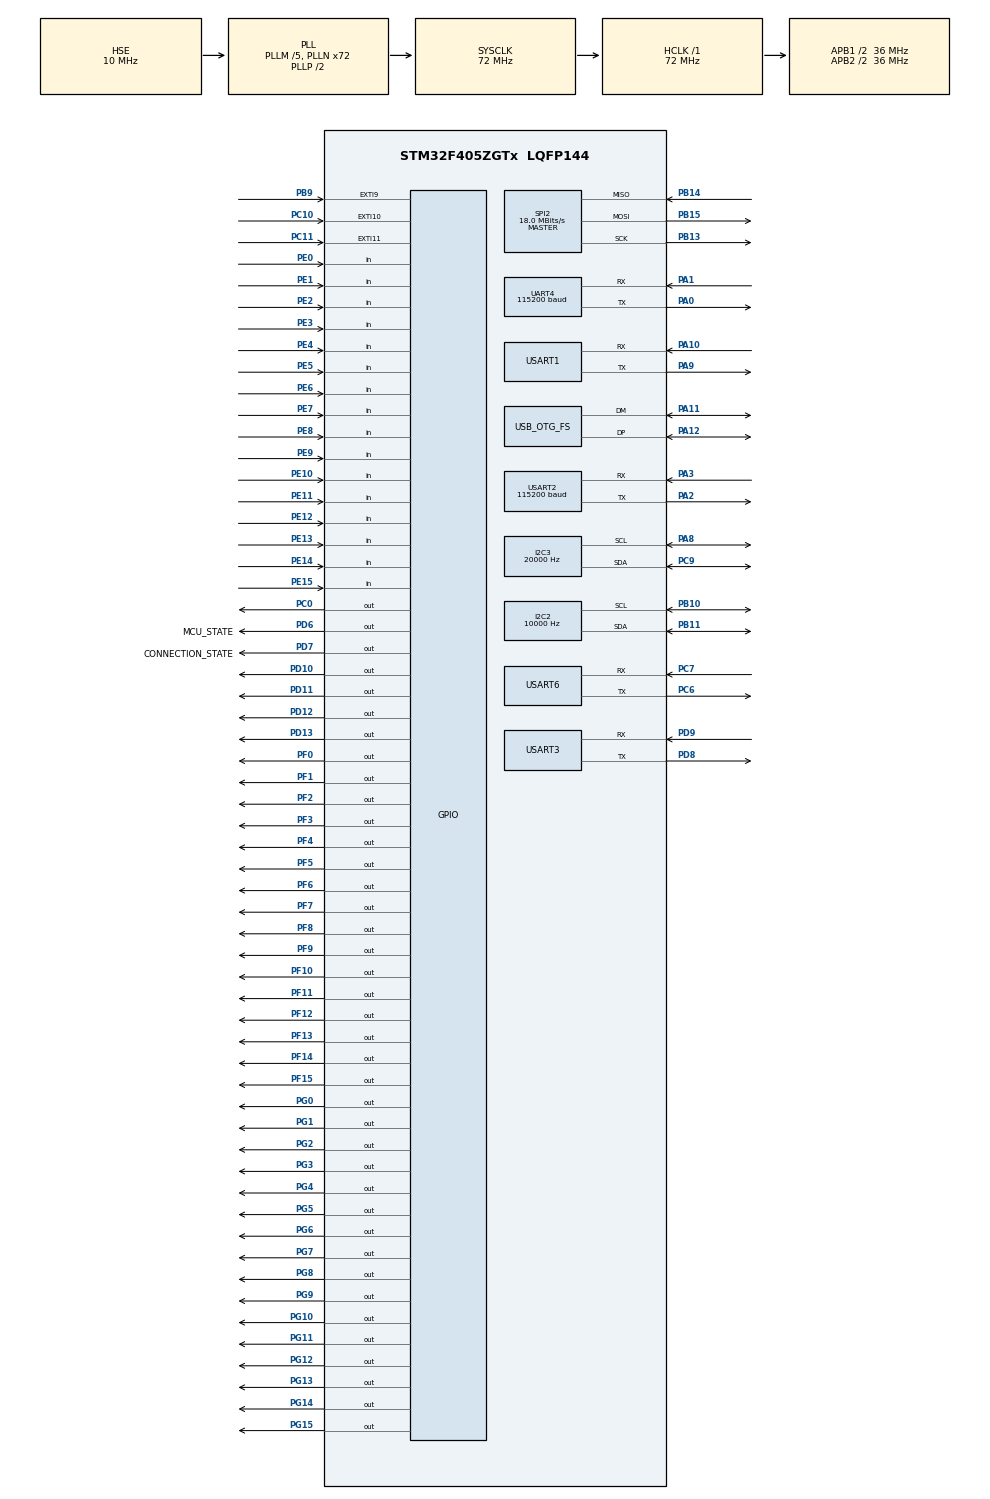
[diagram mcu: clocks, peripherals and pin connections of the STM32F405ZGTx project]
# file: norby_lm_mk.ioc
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Dma.Request0=SPI2_RX
Dma.Request1=SPI2_TX
Dma.SPI2_RX.0.Direction=DMA_PERIPH_TO_MEMORY
Dma.SPI2_RX.0.FIFOMode=DMA_FIFOMODE_DISABLE
Dma.SPI2_RX.0.Instance=DMA1_Stream3
Dma.SPI2_RX.0.MemDataAlignment=DMA_MDATAALIGN_BYTE
Dma.SPI2_RX.0.MemInc=DMA_MINC_ENABLE
Dma.SPI2_RX.0.Mode=DMA_NORMAL
Dma.SPI2_RX.0.PeriphDataAlignment=DMA_PDATAALIGN_BYTE
Dma.SPI2_RX.0.PeriphInc=DMA_PINC_DISABLE
Dma.SPI2_RX.0.Priority=DMA_PRIORITY_LOW
Dma.SPI2_TX.1.Direction=DMA_MEMORY_TO_PERIPH
Dma.SPI2_TX.1.FIFOMode=DMA_FIFOMODE_DISABLE
Dma.SPI2_TX.1.Instance=DMA1_Stream4
Dma.SPI2_TX.1.MemDataAlignment=DMA_MDATAALIGN_BYTE
Dma.SPI2_TX.1.MemInc=DMA_MINC_ENABLE
Dma.SPI2_TX.1.Mode=DMA_NORMAL
Dma.SPI2_TX.1.PeriphDataAlignment=DMA_PDATAALIGN_BYTE
Dma.SPI2_TX.1.PeriphInc=DMA_PINC_DISABLE
Dma.SPI2_TX.1.Priority=DMA_PRIORITY_LOW
I2C2.ClockSpeed=10000
I2C3.ClockSpeed=20000
IWDG.Prescaler=IWDG_PRESCALER_256
IWDG.Reload=4000
Mcu.Family=STM32F4
Mcu.Name=STM32F405ZGTx
Mcu.Package=LQFP144
NVIC.DMA1_Stream3_IRQn=true\:0\:0\:false\:false\:true\:false\:true
NVIC.DMA1_Stream4_IRQn=true\:0\:0\:false\:false\:true\:false\:true
NVIC.EXTI9_5_IRQn=true\:0\:0\:false\:false\:true\:true\:true
NVIC.I2C2_ER_IRQn=true\:0\:0\:false\:false\:true\:true\:true
NVIC.I2C2_EV_IRQn=true\:0\:0\:false\:false\:true\:true\:true
NVIC.I2C3_ER_IRQn=true\:0\:0\:false\:false\:true\:true\:true
NVIC.I2C3_EV_IRQn=true\:0\:0\:false\:false\:true\:true\:true
NVIC.OTG_FS_IRQn=true\:0\:0\:false\:false\:true\:false\:true
NVIC.PriorityGroup=NVIC_PRIORITYGROUP_4
NVIC.SPI2_IRQn=true\:0\:0\:false\:false\:true\:true\:true
NVIC.TIM2_IRQn=true\:0\:0\:false\:false\:true\:true\:true
NVIC.TIM3_IRQn=true\:0\:0\:false\:false\:true\:true\:true
NVIC.TIM5_IRQn=true\:0\:0\:false\:false\:true\:true\:true
NVIC.TIM6_DAC_IRQn=true\:0\:0\:false\:false\:true\:true\:true
NVIC.UART4_IRQn=true\:0\:0\:false\:false\:true\:true\:true
NVIC.USART1_IRQn=true\:0\:0\:false\:false\:true\:true\:true
NVIC.USART2_IRQn=true\:0\:0\:false\:false\:true\:true\:true
NVIC.USART3_IRQn=true\:0\:0\:false\:false\:true\:true\:true
NVIC.USART6_IRQn=true\:0\:0\:false\:false\:true\:true\:true
PA0-WKUP.Mode=Asynchronous
PA0-WKUP.Signal=UART4_TX
PA1.Mode=Asynchronous
PA1.Signal=UART4_RX
PA10.Mode=Asynchronous
PA10.Signal=USART1_RX
PA11.Mode=Device_Only
PA11.Signal=USB_OTG_FS_DM
PA12.Mode=Device_Only
PA12.Signal=USB_OTG_FS_DP
PA13.Mode=Trace_Asynchronous_SW
PA13.Signal=SYS_JTMS-SWDIO
PA14.Mode=Trace_Asynchronous_SW
PA14.Signal=SYS_JTCK-SWCLK
PA2.Mode=Asynchronous
PA2.Signal=USART2_TX
PA3.Mode=Asynchronous
PA3.Signal=USART2_RX
PA8.GPIO_Pu=GPIO_PULLUP
PA8.Mode=I2C
PA8.Signal=I2C3_SCL
PA9.Mode=Asynchronous
PA9.Signal=USART1_TX
PB10.GPIO_Pu=GPIO_PULLUP
PB10.Mode=I2C
PB10.Signal=I2C2_SCL
PB11.GPIO_Pu=GPIO_PULLUP
PB11.Mode=I2C
PB11.Signal=I2C2_SDA
PB13.Mode=Full_Duplex_Master
PB13.Signal=SPI2_SCK
PB14.Mode=Full_Duplex_Master
PB14.Signal=SPI2_MISO
PB15.Mode=Full_Duplex_Master
PB15.Signal=SPI2_MOSI
PB3.Mode=Trace_Asynchronous_SW
PB3.Signal=SYS_JTDO-SWO
PB5.Signal=CAN2_RX
PB6.Signal=CAN2_TX
PB9.GPIO_ModeDefaultEXTI=GPIO_MODE_IT_RISING_FALLING
PB9.GPIO_PuPd=GPIO_PULLUP
PB9.Signal=GPXTI9
PC0.Signal=GPIO_Output
PC10.GPIO_ModeDefaultEXTI=GPIO_MODE_IT_RISING_FALLING
PC10.GPIO_PuPd=GPIO_PULLUP
PC10.Signal=GPXTI10
PC11.GPIO_ModeDefaultEXTI=GPIO_MODE_IT_RISING_FALLING
PC11.GPIO_PuPd=GPIO_PULLUP
PC11.Signal=GPXTI11
PC6.Mode=Asynchronous
PC6.Signal=USART6_TX
PC7.Mode=Asynchronous
PC7.Signal=USART6_RX
PC9.GPIO_Pu=GPIO_PULLUP
PC9.Mode=I2C
PC9.Signal=I2C3_SDA
PD0.Signal=CAN1_RX
PD1.Signal=CAN1_TX
PD10.GPIO_Speed=GPIO_SPEED_FREQ_VERY_HIGH
PD10.PinState=GPIO_PIN_SET
PD10.Signal=GPIO_Output
PD11.GPIO_Speed=GPIO_SPEED_FREQ_VERY_HIGH
PD11.PinState=GPIO_PIN_SET
PD11.Signal=GPIO_Output
PD12.GPIO_Speed=GPIO_SPEED_FREQ_VERY_HIGH
PD12.PinState=GPIO_PIN_SET
PD12.Signal=GPIO_Output
PD13.GPIO_Speed=GPIO_SPEED_FREQ_VERY_HIGH
PD13.PinState=GPIO_PIN_SET
PD13.Signal=GPIO_Output
PD6.GPIO_Label=MCU_STATE
PD6.Signal=GPIO_Output
PD7.GPIO_Label=CONNECTION_STATE
PD7.Signal=GPIO_Output
PD8.Mode=Asynchronous
PD8.Signal=USART3_TX
PD9.Mode=Asynchronous
PD9.Signal=USART3_RX
PE0.Signal=GPIO_Input
PE1.Signal=GPIO_Input
PE10.Signal=GPIO_Input
PE11.Signal=GPIO_Input
PE12.Signal=GPIO_Input
PE13.Signal=GPIO_Input
PE14.Signal=GPIO_Input
PE15.Signal=GPIO_Input
PE2.Signal=GPIO_Input
PE3.Signal=GPIO_Input
PE4.Signal=GPIO_Input
PE5.Signal=GPIO_Input
PE6.Signal=GPIO_Input
PE7.Signal=GPIO_Input
PE8.Signal=GPIO_Input
PE9.Signal=GPIO_Input
PF0.Signal=GPIO_Output
PF1.Signal=GPIO_Output
PF10.Signal=GPIO_Output
PF11.Signal=GPIO_Output
PF12.Signal=GPIO_Output
PF13.Signal=GPIO_Output
PF14.Signal=GPIO_Output
PF15.Signal=GPIO_Output
PF2.Signal=GPIO_Output
PF3.Signal=GPIO_Output
PF4.Signal=GPIO_Output
PF5.Signal=GPIO_Output
PF6.Signal=GPIO_Output
PF7.Signal=GPIO_Output
PF8.Signal=GPIO_Output
PF9.Signal=GPIO_Output
PG0.Signal=GPIO_Output
PG1.Signal=GPIO_Output
PG10.Signal=GPIO_Output
PG11.Signal=GPIO_Output
PG12.Signal=GPIO_Output
PG13.Signal=GPIO_Output
PG14.Signal=GPIO_Output
PG15.Signal=GPIO_Output
PG2.Signal=GPIO_Output
PG3.Signal=GPIO_Output
PG4.Signal=GPIO_Output
PG5.Signal=GPIO_Output
PG6.Signal=GPIO_Output
PG7.Signal=GPIO_Output
PG8.Signal=GPIO_Output
PG9.Signal=GPIO_Output
PH0-OSC_IN.Mode=HSE-External-Oscillator
PH0-OSC_IN.Signal=RCC_OSC_IN
PH1-OSC_OUT.Mode=HSE-External-Oscillator
PH1-OSC_OUT.Signal=RCC_OSC_OUT
ProjectManager.HeapSize=0x400
ProjectManager.StackSize=0x800
ProjectManager.TargetToolchain=MDK-ARM V5.32
RCC.48MHZClocksFreq_Value=48000000
RCC.AHBFreq_Value=72000000
RCC.APB1CLKDivider=RCC_HCLK_DIV2
RCC.APB1Freq_Value=36000000
RCC.APB1TimFreq_Value=72000000
RCC.APB2CLKDivider=RCC_HCLK_DIV2
RCC.APB2Freq_Value=36000000
RCC.APB2TimFreq_Value=72000000
RCC.CortexFreq_Value=72000000
RCC.HCLKFreq_Value=72000000
RCC.HSE_VALUE=10000000
RCC.HSI_VALUE=16000000
RCC.LSE_VALUE=32768
RCC.PLLM=5
RCC.PLLN=72
RCC.PLLQ=3
RCC.RCC_RTC_Clock_SourceVirtual=RCC_RTCCLKSOURCE_HSE_DIV10
RCC.RCC_RTC_Clock_Source_FROM_HSE=RCC_RTCCLKSOURCE_HSE_DIV10
RCC.SYSCLKFreq_VALUE=72000000
RCC.SYSCLKSource=RCC_SYSCLKSOURCE_PLLCLK
RCC.VCOOutputFreq_Value=144000000
RTC.AsynchPrediv=124
RTC.Format=RTC_FORMAT_BIN
RTC.SynchPrediv=7999
SPI2.BaudRatePrescaler=SPI_BAUDRATEPRESCALER_2
SPI2.CalculateBaudRate=18.0 MBits/s
SPI2.Direction=SPI_DIRECTION_2LINES
SPI2.Mode=SPI_MODE_MASTER
SPI2.VirtualType=VM_MASTER
TIM2.Period=1000000
TIM2.Prescaler=71
TIM3.AutoReloadPreload=TIM_AUTORELOAD_PRELOAD_ENABLE
TIM3.Period=1000
TIM3.Prescaler=7199
TIM5.CounterMode=TIM_COUNTERMODE_DOWN
TIM5.Period=1000
TIM5.Prescaler=71
TIM6.AutoReloadPreload=TIM_AUTORELOAD_PRELOAD_ENABLE
TIM6.Period=50
TIM6.Prescaler=7199
UART4.BaudRate=115200
UART4.VirtualMode=Asynchronous
USART1.VirtualMode=VM_ASYNC
USART2.BaudRate=115200
USART2.StopBits=STOPBITS_2
USART2.VirtualMode=VM_ASYNC
USART3.VirtualMode=VM_ASYNC
USART6.VirtualMode=VM_ASYNC
USB_DEVICE.CLASS_NAME_FS=CDC
USB_DEVICE.MANUFACTURER_STRING-CDC_FS=Norby_Linking_Module
USB_DEVICE.PRODUCT_STRING_CDC_FS=Norby_LM Virtual ComPort
USB_DEVICE.VirtualMode-CDC_FS=Cdc
USB_DEVICE.VirtualModeFS=Cdc_FS
USB_OTG_FS.VirtualMode=Device_Only
VP_IWDG_VS_IWDG.Mode=IWDG_Activate
VP_RTC_VS_RTC_Activate.Mode=RTC_Enabled
VP_RTC_VS_RTC_Calendar.Mode=RTC_Calendar
VP_TIM2_VS_ClockSourceINT.Mode=Internal
VP_TIM3_VS_ClockSourceINT.Mode=Internal
VP_TIM5_VS_ClockSourceINT.Mode=Internal
VP_TIM5_VS_OPM.Mode=OPM_bit
VP_TIM6_VS_ClockSourceINT.Mode=Enable_Timer
VP_USB_DEVICE_VS_USB_DEVICE_CDC_FS.Mode=CDC_FS
board=custom

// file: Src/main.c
/* USER CODE BEGIN Header */
/**
  ******************************************************************************
  * @file           : main.c
  * @brief          : Main program body
  ******************************************************************************
  * @attention
  *
  * <h2><center>&copy; Copyright (c) 2020 STMicroelectronics.
  * All rights reserved.</center></h2>
  *
  * This software component is licensed by ST under Ultimate Liberty license
  * SLA0044, the "License"; You may not use this file except in compliance with
  * the License. You may obtain a copy of the License at:
  *                             www.st.com/SLA0044
  *
  ******************************************************************************
  */
/* USER CODE END Header */
#include "main.h"
#include "dma.h"
#include "i2c.h"
#include "iwdg.h"
#include "rtc.h"
#include "spi.h"
#include "tim.h"
#include "usart.h"
#include "usb_device.h"
#include "gpio.h"

/* USER CODE BEGIN Includes */
#include <stdio.h>

//#include "lm.h"
//#include "lm_int_cb.h"
//#include "can_vcp.h"
#include "vcp_time_segmentation.h"
#include "led.h"
#include "cy15b104qn_spi.h"
//test//
#include "modbus.h"
#include "pwr_ch.h"
//test_end//
/* USER CODE END Includes */

/* USER CODE BEGIN PV */
type_VCP_UART vcp;
//type_CAN_VCP can_vcp;
//type_LM_DEVICE lm;
type_MODBUS mb;
type_PWR_CHANNEL sol_pwr_ch;
type_LED_INDICATOR mcu_state_led, con_state_led;

uint8_t tx_data[256], tx_data_len=0; //масив для формирования данных для отправки через VCP
uint8_t rx_data[256], rx_data_len=0;
uint8_t time_slot_flag_100ms = 0, time_slot_flag_10ms = 0, time_slot_flag_5ms = 0, time_slot_flag_1s = 0;
uint8_t timer_slot_5ms_counter = 0;
uint8_t uint8_val = 0, uint8_buff[128] = {0};
uint16_t uint16_val = 0;
int16_t int16_val = 0;
int8_t int8_val = 0;
char str[128];
/* USER CODE END PV */

void SystemClock_Config(void);
/* USER CODE BEGIN PFP */
void blocking_test(void);
/* USER CODE END PFP */

int main(void)
{

  /* MCU Configuration--------------------------------------------------------*/

  /* Reset of all peripherals, Initializes the Flash interface and the Systick. */
  HAL_Init();

  /* Configure the system clock */
  SystemClock_Config();

  /* Initialize all configured peripherals */
  MX_GPIO_Init();
  MX_USB_DEVICE_Init();
  MX_TIM5_Init();
  MX_I2C3_Init();
  MX_TIM6_Init();
  MX_TIM2_Init();
  MX_TIM3_Init();
  MX_I2C2_Init();
  MX_RTC_Init();
  MX_UART4_Init();
  MX_USART2_UART_Init();
  MX_SPI2_Init();
  MX_USART1_UART_Init();
  MX_USART3_UART_Init();
  MX_USART6_UART_Init();
  MX_DMA_Init();
  MX_IWDG_Init();
  /* USER CODE BEGIN 2 */
  //lm_init(&lm);
  //ProcCallbackCmds_Init();
  //can_vcp_init(&can_vcp, &vcp);
  //
  //lm_load_parameters(&lm);
  //led init
  led_init(&mcu_state_led, GPIOD, 6);
  led_init(&con_state_led, GPIOD, 7);
  led_setup(&con_state_led, LED_OFF, 0, 0);
  led_setup(&mcu_state_led, LED_HEART_BEAT, 1000, 0);
  led_alt_setup(&con_state_led, LED_BLINK, 200, 127, 2000);
  led_alt_setup(&mcu_state_led, LED_BLINK, 200, 127, 2000);
  //
  HAL_TIM_Base_Start_IT(&htim6); //LED and 10ms_slot timer
  HAL_TIM_Base_Start_IT(&htim2); //global clock timer
  HAL_TIM_Base_Start_IT(&htim3); //100ms time slot timer
  //
  HAL_UART_Receive_IT(&huart2, mb.rx_data, 1);
  //HAL_UART_Receive_IT(lm.pl._11B.interface.tr_lvl.huart, lm.pl._11B.interface.tr_lvl.rx_data, 1);
  //HAL_UART_Receive_IT(lm.pl._12.interface.tr_lvl.huart, lm.pl._12.interface.tr_lvl.rx_data, 1);
  //HAL_UART_Receive_IT(lm.pl._20.interface.huart, lm.pl._20.interface.rx_data, 1);

  //
  __HAL_DBGMCU_FREEZE_IWDG();
	//
	blocking_test();
  /* USER CODE END 2 */

  /* Infinite loop */
  /* USER CODE BEGIN WHILE */

  while (1)
  {
    if (time_slot_flag_1s){ // 1s
      // сохраняем рабочие параметры
      //lm_save_parameters(&lm);
      //reset flag
			time_slot_flag_1s = 0;
    }
		if (time_slot_flag_100ms){ // 100ms
      // сохраняем время в управляющую струткуру
      //lm.ctrl.global_time_s = clock_get_time_s();
			//формирование кадров телеметрии
      //fill_tmi_and_beacon(&lm);
      //fill_gen_tmi(&lm);
			//опрос мониторов питания
			//pwr_process(&lm.pwr, 100);
			//опрос тремодатчиков
			//tmp_process(&lm.tmp, 100);
			//работа с циклограммой
			//lm_cyclogram_process(&lm, 100);
      //fill_pl_cyclogramm_result(&lm);
      // работа с продолжительными функциями запускаемые через переменную команд (0x02)
      //cmd_process_test_led(MODE_WORK, 100);
      //cmd_process_dcr_write_flight_task(MODE_WORK, CMD_DCR_WRITE_FLIGHT_TASK_1, 100);
      //cmd_process_dcr_write_flight_task(MODE_WORK, CMD_DCR_WRITE_FLIGHT_TASK_2, 100);
      // работа с декор и полетным заданием для декор
      //pn_dcr_process(&lm.pl._dcr, 100); //todo: change  to pn_sol
			//reset flag
			time_slot_flag_100ms = 0;
		}
		if (time_slot_flag_10ms){ // 10ms
      //сброс WDG
      HAL_IWDG_Refresh(&hiwdg);
      //обработка данных принятых от декор и последуещее заполнение памяти кадров ими
      // pn_dcr_process_rx_frames(&lm.pl._dcr, 10);
      //fill_dcr_rx_frame(&lm);
      //
      // fill_pl_iss_last_frame(&lm);
			//reset flag
			time_slot_flag_10ms = 0;
		}
    if (time_slot_flag_5ms){ // 5ms
      //поддрежка работы программной модели ПН_�?СС (включая уровень приложения и транспортный уровень, а также процедуры вычитывания больших объемов данных)
			//pn_11_process(&lm.pl._11A, 5);
      //pn_11_process(&lm.pl._11B, 5);
      //pn_12_process(&lm.pl._12, 5);
      //pn_20_process(&lm.pl._20, 5);
			//reset flag
			time_slot_flag_5ms = 0;
		}
    /* USER CODE END WHILE */

    /* USER CODE BEGIN 3 */
    //*** USB-CAN
    //* обработка команд *//
    //int16_val = cmd_check_to_process(&lm.interface);
    // if (int16_val != CMD_NO_ONE) led_alt_setup(&con_state_led, LED_BLINK, 1400, 127, 2800);
    // switch(int16_val){
    //   case CMD_INIT_LM:
    //     #ifdef DEBUG
    //       printf_time(); printf("cmd: init LM - start\n");
    //     #endif
    //     lm_reset_state(&lm);
    //     #ifdef DEBUG
    //       printf_time(); printf("cmd: init LM - stop\n");
    //     #endif
    //     break;
    //   // case CMD_INIT_ISS_MEM:
    //   //   #ifdef DEBUG
    //   //     printf_time(); printf("cmd: init iss memory\n");
    //   //   #endif
    //   //   ext_mem_format_part(&lm.mem, PART_ISS);
    //   //   break;
    //   // case CMD_INIT_DCR_MEM:
    //   //   #ifdef DEBUG
    //   //     printf_time(); printf("cmd: init decor memory\n");
    //   //   #endif
    //   //   ext_mem_format_part(&lm.mem, PART_DCR);
    //   //   break;
    //   // case CMD_DCR_WRITE_FLIGHT_TASK_1:
    //   //   #ifdef DEBUG
    //   //     printf_time(); printf("cmd: write dcr flight task 1 from_can to dcr-model\n");
    //   //   #endif
    //   //   cmd_process_dcr_write_flight_task(lm.interface.cmd.array[CMD_DCR_WRITE_FLIGHT_TASK_1], CMD_DCR_WRITE_FLIGHT_TASK_1, 0);
    //   //   break;
    //   // case CMD_DCR_WRITE_FLIGHT_TASK_2:
    //   //   #ifdef DEBUG
    //   //     printf_time(); printf("cmd: write dcr flight task 2 from_can to dcr-model\n");
    //   //   #endif
    //   //   cmd_process_dcr_write_flight_task(lm.interface.cmd.array[CMD_DCR_WRITE_FLIGHT_TASK_2], CMD_DCR_WRITE_FLIGHT_TASK_2, 0);
    //   //   break;
    //   case CMD_DBG_LED_TEST:
    //     #ifdef DEBUG
    //       printf_time(); printf("cmd: (dbg) led test 0x%02X\n", lm.interface.cmd.array[CMD_DBG_LED_TEST]);
    //     #endif
    //     cmd_process_test_led(lm.interface.cmd.array[CMD_DBG_LED_TEST], 0);
    //     break;
    //   case CMD_NO_ONE:
    //     // NULL;
    //     break;
    //   default: //если команда в резерве, то реагируем немедленным выполнением
    //     cmd_set_status(&lm.interface, int16_val, 0x7F);
    //     break;
    // }
    // //* обработка командных регистров *//
    // int16_val = cmdreg_check_to_process(&lm.interface);
    // if (int16_val != CMD_NO_ONE) led_alt_setup(&con_state_led, LED_BLINK, 1400, 127, 2800);
    // switch(int16_val){
    //   case CMDREG_LM_MODE:
    //     #ifdef DEBUG
    //       printf_time(); printf("cmdreg: LM mode 0x%02X\n", lm.interface.cmdreg.array[CMDREG_LM_MODE]);
    //     #endif
    //     break;
    //   case CMDREG_PL_PWR_SW:
    //     pwr_on_off(&lm.pwr, lm.interface.cmdreg.array[CMDREG_PL_PWR_SW]);
    //     #ifdef DEBUG
    //       printf_time(); printf("cmdreg: PL pwr sw 0x%02X\n", lm.interface.cmdreg.array[CMDREG_PL_PWR_SW]);
		// 		#endif
    //     break;
    //   case CMDREG_PL_INH_0:
    //   case CMDREG_PL_INH_1:
    //   case CMDREG_PL_INH_2:
    //   case CMDREG_PL_INH_3:
    //   case CMDREG_PL_INH_4:
    //   case CMDREG_PL_INH_5:
    //   case CMDREG_PL_INH_6:
    //   case CMDREG_PL_INH_7:
    //     #ifdef DEBUG
    //       printf_time(); printf("cmdreg: PL inhibit %d: 0x%02X\n", (int16_val - CMDREG_PL_INH_0), lm.interface.cmdreg.array[int16_val]);
    //     #endif
    //     lm_pl_inhibit_set(&lm, (int16_val - CMDREG_PL_INH_0), lm.interface.cmdreg.array[int16_val]);
    //     break;
    //   // case CMDREG_DCR_MODE_SET:
    //   //   pn_dcr_set_mode(&lm.pl._dcr, lm.interface.cmdreg.array[CMDREG_DCR_MODE_SET]);
    //   //   #ifdef DEBUG
    //   //     printf_time(); printf("cmdreg: DCR set mode 0x%02X\n", lm.interface.cmdreg.array[CMDREG_DCR_MODE_SET]);
    //   //   #endif
    //   //   break;
    //   // case CMDREG_PL11A_OUT_SET:
    //   //   pn_11_output_set(&lm.pl._11A, lm.interface.cmdreg.array[int16_val]);
    //   //   #ifdef DEBUG
    //   //     printf_time(); printf("cmdreg: PL11A set output 0x%02X\n", lm.interface.cmdreg.array[int16_val]);
    //   //   #endif
    //   //   break;
    //   // case CMDREG_PL11B_OUT_SET:
    //   //   pn_11_output_set(&lm.pl._11B, lm.interface.cmdreg.array[int16_val]);
    //   //   #ifdef DEBUG
    //   //     printf_time(); printf("cmdreg: PL11B set output 0x%02X\n", lm.interface.cmdreg.array[int16_val]);
    //   //   #endif
    //   //   break;
    //   // case CMDREG_PL12_OUT_SET:
    //   //   pn_12_output_set(&lm.pl._12, lm.interface.cmdreg.array[int16_val]);
    //   //   #ifdef DEBUG
    //   //     printf_time(); printf("cmdreg: PL12 set output 0x%02X\n", lm.interface.cmdreg.array[int16_val]);
    //   //   #endif
    //   //   break;
    //   // case CMDREG_PL20_OUT_SET:
    //   //   pn_20_output_set(&lm.pl._20, lm.interface.cmdreg.array[int16_val]);
    //   //   #ifdef DEBUG
    //   //     printf_time(); printf("cmdreg: PL20 set output 0x%02X\n", lm.interface.cmdreg.array[int16_val]);
    //   //   #endif
    //   //   break;
		// 	// // case CMDREG_CYCLOGRAMS_0:
    //   // case CMDREG_CYCLOGRAMS_1:
    //   //   #ifdef DEBUG
    //   //     printf_time(); printf("cmdreg: cyclograms 0x%04X\n", *(uint16_t*)&lm.interface.cmdreg.array[CMDREG_CYCLOGRAMS_0]);
    //   //   #endif
    //   //   cyclogram_start(&lm.cyclogram, &lm.pl, lm.interface.cmdreg.array[CMDREG_CYCLOGRAMS_0], lm.interface.cmdreg.array[CMDREG_CYCLOGRAMS_1]);
    //   //   break;
    //   // case CMDREG_CONST_MODE:
    //   //   lm.ctrl.constant_mode = lm.interface.cmdreg.array[CMDREG_CONST_MODE] & 0x01;
    //   //   #ifdef DEBUG
    //   //     printf_time(); printf("cmdreg: const_mode 0x%02X\n", lm.interface.cmdreg.array[CMDREG_CONST_MODE]);
    //   //   #endif
    //   //   cyclogram_start(&lm.cyclogram, &lm.pl, lm.interface.cmdreg.array[CMDREG_CYCLOGRAMS_0], lm.interface.cmdreg.array[CMDREG_CYCLOGRAMS_1]);
    //   //   break;
    //   // case CMDREG_TIME_3:
    //   //   clock_set_time_s(*(uint32_t*)&lm.interface.cmdreg.array[CMDREG_TIME_0]);
    //   //   #ifdef DEBUG
    //   //     printf_time(); printf("cmdreg: synch time %d\n", *(uint32_t*)&lm.interface.cmdreg.array[CMDREG_TIME_0]);
    //   //   #endif
    //   //   break;
    //   // case CMDREG_PART_MEM_RD_PTR_3:
    //   //   #ifdef DEBUG
    //   //     printf_time(); printf("cmdreg: set part %d rd_ptr to %d\n", lm.interface.cmdreg.array[CMDREG_PART_MEM_RD_PTR],
    //   //                                                                 *(uint32_t*)&lm.interface.cmdreg.array[CMDREG_PART_MEM_RD_PTR_0]);
		// 	// 	#endif
		// 	// 	ext_mem_set_rd_ptr_for_part(&lm.mem, &lm.interface.cmdreg.array[CMDREG_PART_MEM_RD_PTR],
    //   //                                 (uint32_t*)&lm.interface.cmdreg.array[CMDREG_PART_MEM_RD_PTR_0]);
    //     break;
    //   case CMDREG_SOFT_RESET:
    //     #ifdef DEBUG
    //       printf_time(); printf("cmdreg: soft reset key = %02X\n", lm.interface.cmdreg.array[CMDREG_SOFT_RESET]);
    //     #endif
    //     if (lm.interface.cmdreg.array[CMDREG_SOFT_RESET] == CMDREG_SOFT_RESET_VALUE){
    //       printf_time(); printf("BB, sweety! ^_^\n\n");
    //       while(1){};
    //     }
    //     else lm.interface.cmdreg.array[CMDREG_SOFT_RESET] = 0xFF;
    //     break;
    //   case CMDREG_DBG_LED:
    //     led_alt_setup(&mcu_state_led, LED_BLINK, 1000, lm.interface.cmdreg.array[CMDREG_DBG_LED], 3000);
    //     #ifdef DEBUG
    //       printf_time(); printf("cmdreg: (dbg) led test 0x%02X\n", lm.interface.cmdreg.array[CMDREG_DBG_LED]);
    //     #endif
    //     break;
    //   case CMD_NO_ONE:
    //   default:
    //     // NULL;
    //     break;
    // }
    // //* обработка команды для интерфейса к Декор *//
    // int16_val = dcr_inerface_check_to_process(&lm.interface);
    // if (int16_val != CMD_NO_ONE) led_alt_setup(&con_state_led, LED_BLINK, 1400, 127, 2800);
    // switch(int16_val){
    //   case DCR_INTERFACE_INSTASEND_LENG_OFFSET:
    //     pn_dcr_uart_send(&lm.pl._dcr.uart, lm.interface.dcr_interface.InstaMessage, lm.interface.dcr_interface.InstaMessage[DCR_INTERFACE_INSTASEND_LENG_OFFSET]);
    //     printf("dcr_int:Instasend 0x%02X\n", lm.interface.dcr_interface.InstaMessage[DCR_INTERFACE_INSTASEND_LENG_OFFSET]);
    //     printf_buff(lm.interface.dcr_interface.InstaMessage, lm.interface.dcr_interface.InstaMessage[DCR_INTERFACE_INSTASEND_LENG_OFFSET], '\n');
    //     lm.interface.dcr_interface.InstaMessage[DCR_INTERFACE_INSTASEND_LENG_OFFSET] = 0;  // обнуляем для проверки отправки
    //     break;
    //   case CMD_NO_ONE:
    //   default:
    //     // NULL;
    //     break;
    // }
    // //* обработка команды для интерфейса к ПН_�?СС *//
    // int16_val = pl_iss_inerface_check_to_process(&lm.interface);
    // if (int16_val != CMD_NO_ONE) led_alt_setup(&con_state_led, LED_BLINK, 700, 150, 2800);
    // switch(int16_val){
    //   case PL11A_INTERFACE_INSTASEND_LENG_OFFSET:
    //     pl_iss_get_app_lvl_reprot(PL11A, lm.interface.pl_iss_interface.InstaMessage[PL11A-1], str);
    //     printf("%s", str);
    //     pn_11_can_instasend(&lm.pl._11A, lm.interface.pl_iss_interface.InstaMessage[PL11A-1]);
    //     break;
    //   case PL11B_INTERFACE_INSTASEND_LENG_OFFSET:
    //     pl_iss_get_app_lvl_reprot(PL11B, lm.interface.pl_iss_interface.InstaMessage[PL11B-1], str);
    //     printf("%s", str);
    //     pn_11_can_instasend(&lm.pl._11B, lm.interface.pl_iss_interface.InstaMessage[PL11B-1]);
    //     break;
    //   case PL12_INTERFACE_INSTASEND_LENG_OFFSET:
    //     pl_iss_get_app_lvl_reprot(PL12, lm.interface.pl_iss_interface.InstaMessage[PL12-1], str);
    //     printf("%s", str);
    //     pn_12_can_instasend(&lm.pl._12, lm.interface.pl_iss_interface.InstaMessage[PL12-1]);
    //     break;
    //   case PL20_INTERFACE_INSTASEND_LENG_OFFSET:
    //     pl_iss_get_app_lvl_reprot(PL20, lm.interface.pl_iss_interface.InstaMessage[PL20-1], str);
    //     printf("%s", str);
    //     pn_20_instasend(&lm.pl._20, lm.interface.pl_iss_interface.InstaMessage[PL20-1]);
    //     break;
    //   case CMD_NO_ONE:
    //   default:
    //     // NULL;
    //     break;
    // }
    //*** VCP-CAN. ***//
    //* обработка команд USB-VCP *//
    //if (can_vcp_read_process(&can_vcp)) {
		//	led_alt_setup(&con_state_led, LED_BLINK, 700, 100, 2800);
		//}
  }
  /* USER CODE END 3 */
}

void SystemClock_Config(void)
{
  RCC_OscInitTypeDef RCC_OscInitStruct = {0};
  RCC_ClkInitTypeDef RCC_ClkInitStruct = {0};

  /** Configure the main internal regulator output voltage
  */
  __HAL_RCC_PWR_CLK_ENABLE();
  __HAL_PWR_VOLTAGESCALING_CONFIG(PWR_REGULATOR_VOLTAGE_SCALE1);
  /** Initializes the RCC Oscillators according to the specified parameters
  * in the RCC_OscInitTypeDef structure.
  */
  RCC_OscInitStruct.OscillatorType = RCC_OSCILLATORTYPE_LSI|RCC_OSCILLATORTYPE_HSE;
  RCC_OscInitStruct.HSEState = RCC_HSE_ON;
  RCC_OscInitStruct.LSIState = RCC_LSI_ON;
  RCC_OscInitStruct.PLL.PLLState = RCC_PLL_ON;
  RCC_OscInitStruct.PLL.PLLSource = RCC_PLLSOURCE_HSE;
  RCC_OscInitStruct.PLL.PLLM = 5;
  RCC_OscInitStruct.PLL.PLLN = 72;
  RCC_OscInitStruct.PLL.PLLP = RCC_PLLP_DIV2;
  RCC_OscInitStruct.PLL.PLLQ = 3;
  if (HAL_RCC_OscConfig(&RCC_OscInitStruct) != HAL_OK)
  {
    Error_Handler();
  }
  /** Initializes the CPU, AHB and APB buses clocks
  */
  RCC_ClkInitStruct.ClockType = RCC_CLOCKTYPE_HCLK|RCC_CLOCKTYPE_SYSCLK
                              |RCC_CLOCKTYPE_PCLK1|RCC_CLOCKTYPE_PCLK2;
  RCC_ClkInitStruct.SYSCLKSource = RCC_SYSCLKSOURCE_PLLCLK;
  RCC_ClkInitStruct.AHBCLKDivider = RCC_SYSCLK_DIV1;
  RCC_ClkInitStruct.APB1CLKDivider = RCC_HCLK_DIV2;
  RCC_ClkInitStruct.APB2CLKDivider = RCC_HCLK_DIV2;

  if (HAL_RCC_ClockConfig(&RCC_ClkInitStruct, FLASH_LATENCY_2) != HAL_OK)
  {
    Error_Handler();
  }
}

/* USER CODE BEGIN 4 */

void blocking_test(void)
{
  uint8_t i;
  // test
  printf_time();
  printf("Start blocking test\n");
  //

  pwr_ch_init(&sol_pwr_ch, &hi2c3, 0x41, 8, GPIOF, 0, GPIOF, 1, GPIOF, 2);
  pwr_ch_on_off(&sol_pwr_ch, 1);
	printf("\t sol pwr on \n");
	HAL_Delay(2000);

  mb_init(&mb, &huart2);

  mb_queue_fill(&mb, 0, 2, 3, 0x113, 1, NULL);
  mb_queue_fill(&mb, 1, 2, 3, 0x114, 1, NULL);
  mb_queue_fill(&mb, 2, 2, 3, 0x115, 1, NULL);
  mb_queue_fill(&mb, 3, 2, 3, 0x116, 1, NULL);
  mb_queue_run(&mb);
  HAL_Delay(5);
  for(i=0; i<200; i++){
    HAL_Delay(5);
    mb_process_transaction(&mb, 5);
    mb_queue_process(&mb, 5);
    }

  printf_time();
  printf("Finish test\n\n");
}

void HAL_TIM_PeriodElapsedCallback(TIM_HandleTypeDef *htim)
{
	if (htim == &htim6) {
    timer_slot_5ms_counter += 1;
    if (timer_slot_5ms_counter >= 2){ //создание искусственного события c периодом 10 мс
      timer_slot_5ms_counter = 0;
      time_slot_flag_10ms = 1;
    }
    led_processor(&mcu_state_led, 5);
    led_processor(&con_state_led, 5);
		time_slot_flag_5ms = 5;
	}
	if (htim == &htim2) {
		//lm.ctrl.global_time_s += 1;
    time_slot_flag_1s = 1;
	}
	if (htim == &htim3) {
		time_slot_flag_100ms = 1;
	}
}

void HAL_I2C_MasterTxCpltCallback(I2C_HandleTypeDef *hi2c)
{
	if(hi2c == &hi2c3){
//		pwr_cb_it_process(&lm.pwr, 0);
	}
	if(hi2c == &hi2c2){
//		tmp_cb_it_process(&lm.tmp, 0);
	}
}

void HAL_I2C_MasterRxCpltCallback(I2C_HandleTypeDef *hi2c)
{
	if(hi2c == &hi2c3){
//		pwr_cb_it_process(&lm.pwr, 0);
	}
	if(hi2c == &hi2c2){
//		tmp_cb_it_process(&lm.tmp, 0);
	}
}

void HAL_I2C_ErrorCallback(I2C_HandleTypeDef *hi2c)
{
	if(hi2c == &hi2c3){
//		pwr_cb_it_process(&lm.pwr, 1);
	}
	if(hi2c == &hi2c2){
//		tmp_cb_it_process(&lm.tmp, 1);
	}
}

void HAL_GPIO_EXTI_Callback(uint16_t GPIO_Pin)
{
//	pwr_alert_gd_it_process(&lm.pwr, GPIO_Pin);
//	tmp_alert_it_process(&lm.tmp, GPIO_Pin);
	led_alt_setup(&mcu_state_led, 2, 600, 127, 10000);
}

void HAL_UART_RxCpltCallback(UART_HandleTypeDef *huart_req)
{
	if(huart_req == &huart2){ // PL_SOL
    mb_int_rx_huart_cb(&mb);
	}
}

void HAL_UART_TxCpltCallback(UART_HandleTypeDef *huart_req)
{
	if(huart_req == &huart2){ // PL_SOL
    //
  }
}

void HAL_UART_ErrorCallback(UART_HandleTypeDef *huart_req)
{
  if(huart_req == &huart2){ // PL_SOL
    mb_int_rx_huart_cb(&mb);  //todo:при работе возникает большое количество HAL_UART_ERROR_ORE (начало приема нового символа, когда старый еще не обработае), костыль перекрывающий эту ошибку
	}
}

void HAL_SPI_TxRxCpltCallback(SPI_HandleTypeDef *hspi)
{
  if (hspi == &hspi2){
//    lm.mem.cy15b104[0].rx_tx_cmplt_flag = 1;
  }
}

void HAL_SPI_ErrorCallback(SPI_HandleTypeDef *hspi)
{
  if (hspi == &hspi2){
//    lm.mem.cy15b104[0].rx_tx_cmplt_flag = -1;
  }
}

/* USER CODE END 4 */

void Error_Handler(void)
{
  /* USER CODE BEGIN Error_Handler_Debug */
  /* User can add his own implementation to report the HAL error return state */
	printf("HAL error\n");
  /* USER CODE END Error_Handler_Debug */
}

/************************ (C) COPYRIGHT STMicroelectronics *****END OF FILE****/
